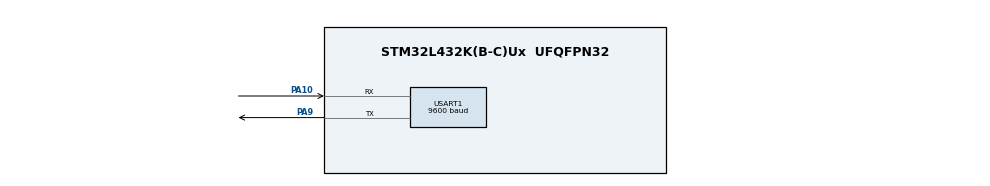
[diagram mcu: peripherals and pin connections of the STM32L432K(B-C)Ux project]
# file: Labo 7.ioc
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Dma.Request0=USART1_RX
Dma.Request1=USART1_TX
Dma.USART1_RX.0.Direction=DMA_PERIPH_TO_MEMORY
Dma.USART1_RX.0.Instance=DMA1_Channel5
Dma.USART1_RX.0.MemDataAlignment=DMA_MDATAALIGN_BYTE
Dma.USART1_RX.0.MemInc=DMA_MINC_ENABLE
Dma.USART1_RX.0.Mode=DMA_NORMAL
Dma.USART1_RX.0.PeriphDataAlignment=DMA_PDATAALIGN_BYTE
Dma.USART1_RX.0.PeriphInc=DMA_PINC_DISABLE
Dma.USART1_RX.0.Priority=DMA_PRIORITY_LOW
Dma.USART1_TX.1.Direction=DMA_MEMORY_TO_PERIPH
Dma.USART1_TX.1.Instance=DMA1_Channel4
Dma.USART1_TX.1.MemDataAlignment=DMA_MDATAALIGN_BYTE
Dma.USART1_TX.1.MemInc=DMA_MINC_ENABLE
Dma.USART1_TX.1.Mode=DMA_NORMAL
Dma.USART1_TX.1.PeriphDataAlignment=DMA_PDATAALIGN_BYTE
Dma.USART1_TX.1.PeriphInc=DMA_PINC_DISABLE
Dma.USART1_TX.1.Priority=DMA_PRIORITY_LOW
Mcu.Family=STM32L4
Mcu.Name=STM32L432K(B-C)Ux
Mcu.Package=UFQFPN32
NVIC.DMA1_Channel4_IRQn=true\:0\:0\:false\:false\:true\:false\:true\:true
NVIC.DMA1_Channel5_IRQn=true\:0\:0\:false\:false\:true\:false\:true\:true
NVIC.PriorityGroup=NVIC_PRIORITYGROUP_4
PA10.Mode=Asynchronous
PA10.Signal=USART1_RX
PA9.Mode=Asynchronous
PA9.Signal=USART1_TX
ProjectManager.HeapSize=0x200
ProjectManager.StackSize=0x400
ProjectManager.TargetToolchain=STM32CubeIDE
RCC.HSE_VALUE=8000000
RCC.HSI48_VALUE=48000000
RCC.HSI_VALUE=16000000
RCC.LSE_VALUE=32768
RCC.MSI_VALUE=4000000
RCC.VCOOutputFreq_Value=32000000
USART1.BaudRate=9600
USART1.VirtualMode-Asynchronous=VM_ASYNC
board=custom

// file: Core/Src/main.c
/* USER CODE BEGIN Header */
/**
  ******************************************************************************
  * @file           : main.c
  * @brief          : Main program body
  ******************************************************************************
  * @attention
  *
  * Copyright (c) 2022 STMicroelectronics.
  * All rights reserved.
  *
  * This software is licensed under terms that can be found in the LICENSE file
  * in the root directory of this software component.
  * If no LICENSE file comes with this software, it is provided AS-IS.
  *
  ******************************************************************************
  */
/* USER CODE END Header */
#include "main.h"

/* USER CODE BEGIN PM */
uint8_t UART1_rxBuffer[12] = {0};
/* USER CODE END PM */

UART_HandleTypeDef huart1;
DMA_HandleTypeDef hdma_usart1_rx;
DMA_HandleTypeDef hdma_usart1_tx;

void SystemClock_Config(void);
static void MX_GPIO_Init(void);
static void MX_DMA_Init(void);
static void MX_USART1_UART_Init(void);

/* USER CODE BEGIN 0 */
uint8_t dataArrived = 0;
uint8_t data[12]="";
/* USER CODE END 0 */

int main(void)
{
  /* USER CODE BEGIN 1 */
	uint8_t Prueba [] = "¡¡¡Hola mundo!!! \r\n " ; //Datos para enviar

  /* USER CODE END 1 */

  /* MCU Configuration--------------------------------------------------------*/

  /* Reset of all peripherals, Initializes the Flash interface and the Systick. */
  HAL_Init();

  /* Configure the system clock */
  SystemClock_Config();

  /* Initialize all configured peripherals */
  MX_GPIO_Init();
  MX_DMA_Init();
  MX_USART1_UART_Init();

  /* Infinite loop */
  /* USER CODE BEGIN WHILE */
  HAL_UART_Receive_DMA(&huart1, dayta, 12);
  while(!dataArrived)
  while (1)
  {
    /* USER CODE END WHILE */
	  HAL_UART_Transmit_DMA(&huart2, (uint8_t*)"Hola \n\r", strlen("Hola\n\r"));
	  HAL_Delay(1000);
  }
}

void SystemClock_Config(void)
{
  RCC_OscInitTypeDef RCC_OscInitStruct = {0};
  RCC_ClkInitTypeDef RCC_ClkInitStruct = {0};

  /** Configure the main internal regulator output voltage
  */
  if (HAL_PWREx_ControlVoltageScaling(PWR_REGULATOR_VOLTAGE_SCALE1) != HAL_OK)
  {
    Error_Handler();
  }

  /** Initializes the RCC Oscillators according to the specified parameters
  * in the RCC_OscInitTypeDef structure.
  */
  RCC_OscInitStruct.OscillatorType = RCC_OSCILLATORTYPE_MSI;
  RCC_OscInitStruct.MSIState = RCC_MSI_ON;
  RCC_OscInitStruct.MSICalibrationValue = 0;
  RCC_OscInitStruct.MSIClockRange = RCC_MSIRANGE_6;
  RCC_OscInitStruct.PLL.PLLState = RCC_PLL_NONE;
  if (HAL_RCC_OscConfig(&RCC_OscInitStruct) != HAL_OK)
  {
    Error_Handler();
  }

  /** Initializes the CPU, AHB and APB buses clocks
  */
  RCC_ClkInitStruct.ClockType = RCC_CLOCKTYPE_HCLK|RCC_CLOCKTYPE_SYSCLK
                              |RCC_CLOCKTYPE_PCLK1|RCC_CLOCKTYPE_PCLK2;
  RCC_ClkInitStruct.SYSCLKSource = RCC_SYSCLKSOURCE_MSI;
  RCC_ClkInitStruct.AHBCLKDivider = RCC_SYSCLK_DIV1;
  RCC_ClkInitStruct.APB1CLKDivider = RCC_HCLK_DIV1;
  RCC_ClkInitStruct.APB2CLKDivider = RCC_HCLK_DIV1;

  if (HAL_RCC_ClockConfig(&RCC_ClkInitStruct, FLASH_LATENCY_0) != HAL_OK)
  {
    Error_Handler();
  }
}

static void MX_USART1_UART_Init(void)
{

  huart1.Instance = USART1;
  huart1.Init.BaudRate = 9600;
  huart1.Init.WordLength = UART_WORDLENGTH_8B;
  huart1.Init.StopBits = UART_STOPBITS_1;
  huart1.Init.Parity = UART_PARITY_NONE;
  huart1.Init.Mode = UART_MODE_TX_RX;
  huart1.Init.HwFlowCtl = UART_HWCONTROL_NONE;
  huart1.Init.OverSampling = UART_OVERSAMPLING_16;
  huart1.Init.OneBitSampling = UART_ONE_BIT_SAMPLE_DISABLE;
  huart1.AdvancedInit.AdvFeatureInit = UART_ADVFEATURE_NO_INIT;
  if (HAL_UART_Init(&huart1) != HAL_OK)
  {
    Error_Handler();
  }

}

static void MX_DMA_Init(void)
{

  /* DMA controller clock enable */
  __HAL_RCC_DMA1_CLK_ENABLE();

  /* DMA interrupt init */
  /* DMA1_Channel4_IRQn interrupt configuration */
  HAL_NVIC_SetPriority(DMA1_Channel4_IRQn, 0, 0);
  HAL_NVIC_EnableIRQ(DMA1_Channel4_IRQn);
  /* DMA1_Channel5_IRQn interrupt configuration */
  HAL_NVIC_SetPriority(DMA1_Channel5_IRQn, 0, 0);
  HAL_NVIC_EnableIRQ(DMA1_Channel5_IRQn);

}

static void MX_GPIO_Init(void)
{

  /* GPIO Ports Clock Enable */
  __HAL_RCC_GPIOA_CLK_ENABLE();

}

/* USER CODE BEGIN 4 */
void HAL_UART_RxCpltCallback(UART_HandleTypeDef *huart){
	dataArrived=1;
}
/* USER CODE END 4 */

void Error_Handler(void)
{
  __disable_irq();
  while (1)
  {
  }
}
